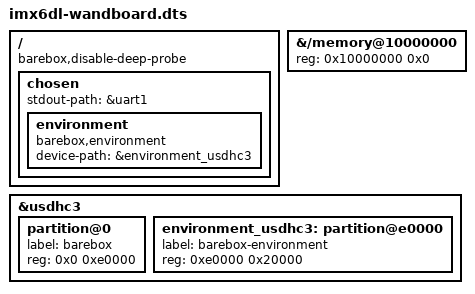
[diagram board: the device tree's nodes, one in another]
#include <arm/nxp/imx/imx6dl-wandboard.dts>
#include <dt-bindings/gpio/gpio.h>
#include "imx6dl.dtsi"

/ {
	barebox,disable-deep-probe;

	chosen {
		stdout-path = &uart1;

		environment {
			compatible = "barebox,environment";
			device-path = &environment_usdhc3;
		};
	};
};

&{/memory@10000000} {
	reg = <0x10000000 0x0>;
};

&usdhc3 {
	#address-cells = <1>;
	#size-cells = <1>;

	partition@0 {
		label = "barebox";
		reg = <0x0 0xe0000>;
	};

	environment_usdhc3: partition@e0000 {
		label = "barebox-environment";
		reg = <0xe0000 0x20000>;
	};
};
